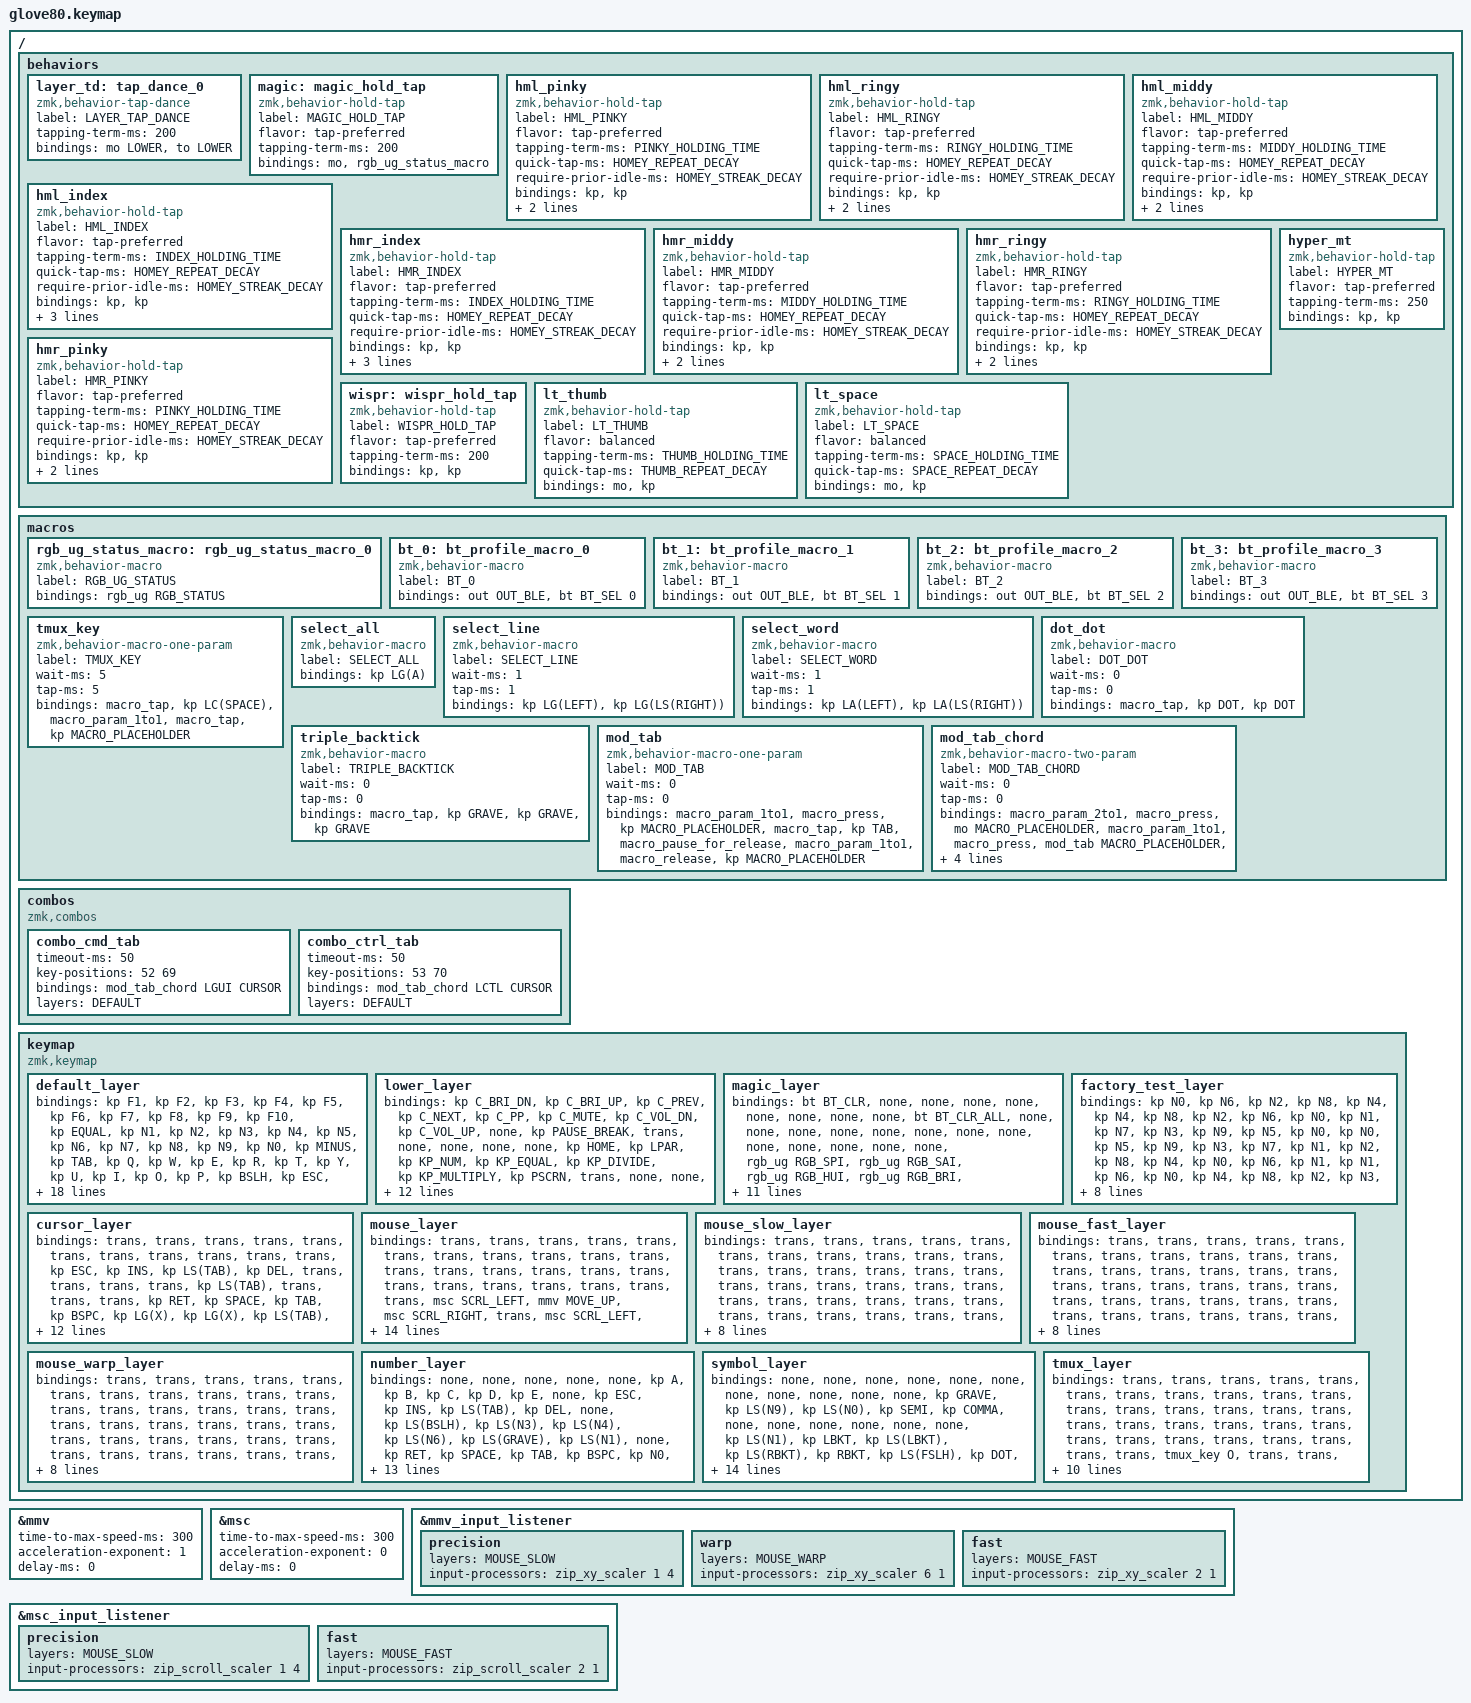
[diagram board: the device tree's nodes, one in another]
// V2 — Home Row Mods (HRM), sunaku-flavored, layered onto V1 stock baseline.
// V1 (verbatim moergo-sc/glove80-zmk-config@34888be8) is preserved in git history
// at commit a61129d. This file diverges from V1 only on the default_layer's home
// row (row 4), where A/S/D/F and J/K/L/; become home row mods.
//
// HRM terminology (defined here on first use):
//   - HRM (Home Row Mod): a key on the home row (A S D F or J K L ;) that
//     behaves as a letter when tapped and as a modifier (Shift/Ctrl/Alt/Cmd)
//     when held. The goal is to never reach away from the home row to chord.
//   - hold-tap behavior: a ZMK primitive — one key, two outputs, chosen by
//     whether you tapped or held it. Same primitive that powers V1's &layer_td.
//   - mod-tap (&mt): ZMK's stock hold-tap where the hold side is a modifier.
//     We don't use &mt directly because we need finer control than its defaults.
//   - positional hold-tap: a hold-tap that also checks WHICH other key was
//     pressed during the hold window. If the other key is on the same hand,
//     the HRM resolves to a tap (letter) instead of a hold (modifier). This is
//     the primary defense against accidental modifier activation during typing.
//   - bilateral combinations: the convention that modifier-key chords use one
//     hand to hold the modifier and the OTHER hand to tap the modified key.
//     The positional hold-tap (above) nudges you toward this: a same-hand
//     key pressed mid-hold makes the HRM resolve to a tap, not a modifier.
//   - hold-while-undecided: a ZMK property that pre-presses the hold side
//     during the "undecided" window so that releasing the key without pressing
//     anything else still types the tap letter. Powers SHIFT_FORGIVENESS.
//   - require-prior-idle-ms ("streak decay"): blocks the hold side from firing
//     if any key was pressed within the last N ms. The big anti-misfire knob.
//   - quick-tap-ms ("repeat decay"): if you tapped the key very recently, the
//     next press is forced to be a tap (lets you "tap-then-hold" for auto-repeat).
//   - conditional layer: a ZMK construct that auto-activates a layer when one
//     or more other layers are already active. (Not used in V2; mentioned for
//     vocabulary completeness because V3+ may use it.)
//
// HRM configuration knobs are grouped in the V2 CONFIGURATION block below.
// Change DIFFICULTY_LEVEL to retune all hold timings with one number.

/*
 * Copyright (c) 2020 The ZMK Contributors
 *
 * SPDX-License-Identifier: MIT
 */

#include <behaviors.dtsi>
#include <dt-bindings/zmk/keys.h>
#include <dt-bindings/zmk/bt.h>
#include <dt-bindings/zmk/ext_power.h>
#include <dt-bindings/zmk/outputs.h>
#include <dt-bindings/zmk/rgb.h>
#include <dt-bindings/zmk/pointing.h>
#include <input/processors.dtsi>

#define HYPER LC(LS(LG(LALT)))

// =============================================================================
// V2 CONFIGURATION (sunaku-flavored HRM)
// =============================================================================

// OPERATING_SYSTEM — affects modifier order. Long-term goal of this repo is a
// macOS keyboard workflow, so we use macOS-tuned CAGS order. On macOS, Cmd is
// the everyday-shortcut modifier (Cmd+C, Cmd+V), so it lives on the strong
// middle finger where Linux/Windows put Ctrl. CAGS = Ctrl / Alt / Cmd / Shift.
#define OPERATING_SYSTEM 'M'

// DIFFICULTY_LEVEL — sunaku's noob-friendly sensitivity preset.
//   1 = 500 ms (very slow, very safe)
//   2 = 400 ms (slower, safe)
//   3 = 300 ms (normal)
//   4 = 200 ms (faster)               <-- current
//   5 = 100 ms (expert, lots of misfires until your hands learn)
// Bump it up as your fingers get used to HRM. Lower the number, longer the
// hold needed before a key counts as a modifier.
#define DIFFICULTY_LEVEL 4

// TAPPING_RESOLUTION — the "base" hold time derived from DIFFICULTY_LEVEL.
// Formula matches sunaku exactly: level 4 → (6 - 4) * 100 = 200 ms.
// Per-finger holding times are offsets ON TOP of this number, see below.
#define TAPPING_RESOLUTION ((6 - DIFFICULTY_LEVEL) * 100)

// Per-finger holding times. Weaker fingers (pinky) get more time so a
// natural slower press doesn't accidentally fire the modifier. Sunaku's
// offsets: index +30, middle +60, ring +90, pinky +120. With level 4:
//   index  =  230 ms (shift — fastest, because shift is most natural to hold)
//   middle =  260 ms (cmd on macOS)
//   ring   =  290 ms (alt)
//   pinky  =  320 ms (ctrl — slowest, because pinky is the weakest finger)
#define INDEX_HOLDING_TIME (TAPPING_RESOLUTION + 30)
#define MIDDY_HOLDING_TIME (TAPPING_RESOLUTION + 60)
#define RINGY_HOLDING_TIME (TAPPING_RESOLUTION + 90)
#define PINKY_HOLDING_TIME (TAPPING_RESOLUTION + 120)

// HOMEY_STREAK_DECAY — the "require-prior-idle-ms" value. If you typed any key
// in the last N ms, the HRM is FORCED to resolve as a tap. This is the big
// anti-misfire knob for typing. Level 4 → 200 ms of idle required before an
// HRM can resolve as a modifier. Sounds long, but it only kicks in mid-word.
#define HOMEY_STREAK_DECAY TAPPING_RESOLUTION

// HOMEY_REPEAT_DECAY — the "quick-tap-ms" value. If you tapped the same HRM
// in the last N ms, the next press resolves as a tap (letter). Lets you do
// "tap, then hold" for OS-level key auto-repeat: tap A once, hold A → "aaaa".
#define HOMEY_REPEAT_DECAY (TAPPING_RESOLUTION + 150)

// THUMB_HOLDING_TIME / THUMB_REPEAT_DECAY — timing for the thumb layer-tap keys
// (Backspace→Cursor, Enter→Mouse). Matches sunaku: thumbs get a little MORE
// hold time than the home row (+50 on the base) because a thumb resting on its
// key shouldn't trip the layer. quick-tap lets a fast double-press auto-repeat
// the tapped key. Both scale with DIFFICULTY_LEVEL like the home row timings.
#define THUMB_HOLDING_TIME (TAPPING_RESOLUTION + 50)
#define THUMB_REPEAT_DECAY (TAPPING_RESOLUTION + 150)

// SPACE_* — the Symbol layer lives on the Space thumb (tap Space, hold Symbol).
// Space is the most-pressed key, so it gets its own behavior: same balanced
// flavor and hold time as the thumbs, but a SHORTER quick-tap window
// (TAPPING_RESOLUTION) so tap-then-type isn't swallowed as auto-repeat. Matches
// sunaku's defaults. (He also offers an opt-in "space forgiveness" mode —
// tap-preferred + retro-tap — for fewer misfires; left off here to match him.)
#define SPACE_HOLDING_TIME THUMB_HOLDING_TIME
#define SPACE_REPEAT_DECAY TAPPING_RESOLUTION

// =============================================================================
// V3 MOUSE CONFIGURATION
// =============================================================================
// Tuning the ZMK pointing subsystem. Defaults are conservative; these values
// match sunaku's choices and feel reactive without being twitchy on 1440p+.
//
// MOUSE_MOVE_MAX — peak cursor speed (pixels per tick at full speed).
//   Higher = cursor crosses screen faster. 600 is sunaku's default for HiDPI.
// MOUSE_SCROLL_MAX — peak scroll speed (lines per tick).
//   Lower than move because scroll is per-line, not per-pixel.
// MOUSE_TIME_TO_MAX — ramp duration from 0 to peak (ms).
//   300 ms feels real-mouse-like; <200 ms is twitchy; >500 ms feels sluggish.
// MOUSE_ACCEL_EXP — 0 = linear ramp, 1 = quadratic (gaming-mouse feel).
#define ZMK_POINTING_DEFAULT_MOVE_VAL 600
#define ZMK_POINTING_DEFAULT_SCRL_VAL 20

// CAGS modifier order (macOS-tuned). Pinky → index = Ctrl, Alt, Cmd, Shift.
// Mirrored on both hands. On macOS, Cmd lands on the strong middle finger
// where Ctrl lives on Linux/Windows — because Cmd is the everyday shortcut
// modifier in macOS (Cmd+C, Cmd+V, Cmd+Tab).
#define LH_PINKY_MOD LCTL
#define LH_RINGY_MOD LALT
#define LH_MIDDY_MOD LGUI
#define LH_INDEX_MOD LSFT
#define RH_INDEX_MOD LSFT
#define RH_MIDDY_MOD LGUI
#define RH_RINGY_MOD LALT
#define RH_PINKY_MOD LCTL

// SHIFT_FORGIVENESS — on. When you hold a shift HRM and release it without
// pressing another key, the underlying letter (F or J) is typed instead of
// nothing. Prevents the "I lingered too long and nothing happened" surprise.
// Implemented via the `hold-while-undecided` ZMK property on the two index
// HRMs. Available in our pinned ZMK (v25.11, well past the v24.08-beta1
// threshold required for `hold-while-undecided`).

// BILATERAL COMBINATIONS — enforced by the positional hold-tap, not by a
// dedicated layer. Each HRM's hold-trigger-key-positions lists the OPPOSITE
// hand, so a same-hand key pressed during the hold window makes the HRM resolve
// to a tap (letter) instead of a modifier. That is what stops same-hand
// misfires while typing. A deliberately held modifier still applies to whatever
// you press next, same hand included — that is inherent to home row mods
// (sunaku's behave the same way), not something the firmware can prevent.

// Glove80 key-position numbering (sunaku's layout — used by hold-trigger-key-positions).
// 80 keys total, numbered 0–79. Left hand = positions 0–51, 64–71, plus split
// thumbs 52–54, 69–71. Right hand = positions 5–9 + 16–21 + 28–33 + 40–45 +
// 58–63 + 75–79 + thumbs 55–57, 72–74. Used by ZMK to decide if "the other
// key I just pressed" is on the same hand or the opposite hand.
//
// Visual:
//   |------------------------|------------------------|
//   | LEFT_HAND_KEYS         |        RIGHT_HAND_KEYS |
//   |                        |                        |
//   |  0  1  2  3  4         |          5  6  7  8  9 |
//   | 10 11 12 13 14 15      |      16 17 18 19 20 21 |
//   | 22 23 24 25 26 27      |      28 29 30 31 32 33 |
//   | 34 35 36 37 38 39      |      40 41 42 43 44 45 |
//   | 46 47 48 49 50 51      |      58 59 60 61 62 63 |
//   | 64 65 66 67 68         |         75 76 77 78 79 |
//   |                69 52   |   57 74                |
//   |                 70 53  |  56 73                 |
//   |                  71 54 | 55 72                  |
//   |------------------------|------------------------|

#define LEFT_HAND_KEYS  \
     0  1  2  3  4      \
    10 11 12 13 14 15   \
    22 23 24 25 26 27   \
    34 35 36 37 38 39   \
    46 47 48 49 50 51   \
    64 65 66 67 68      \
    52 53 54 69 70 71

#define RIGHT_HAND_KEYS \
     5  6  7  8  9      \
    16 17 18 19 20 21   \
    28 29 30 31 32 33   \
    40 41 42 43 44 45   \
    58 59 60 61 62 63   \
    75 76 77 78 79      \
    55 56 57 72 73 74

// =============================================================================
// LAYER NUMBERS
// =============================================================================
// V1 layers preserved. V3 adds CURSOR + MOUSE + three Mouse speed sublayers.
// V4 adds NUMBER + SYMBOL (Miryoku-style bilateral layers).
#define DEFAULT      0
#define LOWER        1
#define MAGIC        2
#define FACTORY_TEST 3
#define CURSOR       4
#define MOUSE        5
#define MOUSE_SLOW   6
#define MOUSE_FAST   7
#define MOUSE_WARP   8
#define NUMBER       9
#define SYMBOL       10
#define TMUX         11

/ {
    behaviors {
        // V1 tap-dance for the LOWER thumb key (unchanged).
        // First tap (or hold) = momentary, second tap = toggle.
        layer_td: tap_dance_0 {
            compatible = "zmk,behavior-tap-dance";
            label = "LAYER_TAP_DANCE";
            #binding-cells = <0>;
            tapping-term-ms = <200>;
            bindings = <&mo LOWER>, <&to LOWER>;
        };

        // V1 magic-key hold-tap (unchanged).
        // Hold = MAGIC layer, tap = RGB status indicator macro.
        magic: magic_hold_tap {
            compatible = "zmk,behavior-hold-tap";
            label = "MAGIC_HOLD_TAP";
            #binding-cells = <2>;
            flavor = "tap-preferred";
            tapping-term-ms = <200>;
            bindings = <&mo>, <&rgb_ug_status_macro>;
        };

        // =====================================================================
        // V2 home row mod hold-tap behaviors (8 total: 4 per hand, one per finger)
        // =====================================================================
        // Naming: hml_* = HRM Left, hmr_* = HRM Right. Suffix is the finger.
        //
        // Each behavior is a positional hold-tap:
        //   - flavor = tap-preferred: only resolves to hold if you actually
        //     hold past the tapping-term. Safest for fast typists.
        //   - tapping-term-ms: how long to hold before "hold" can fire.
        //   - quick-tap-ms (HOMEY_REPEAT_DECAY): tap-then-hold = auto-repeat.
        //   - require-prior-idle-ms (HOMEY_STREAK_DECAY): blocks holds during
        //     fast typing streaks.
        //   - hold-trigger-key-positions: only resolve as hold if the second
        //     key is on the OPPOSITE hand. Same-hand presses force a tap.
        //   - hold-trigger-on-release: defers the position check until release,
        //     letting fast rolls on the same hand resolve cleanly as taps.
        //   - bindings = <&kp>, <&kp>: hold side presses the modifier, the
        //     tap side types the letter (standard mod-tap).
        //   - hold-while-undecided: on the index/shift HRMs only, enables
        //     SHIFT_FORGIVENESS (release without other keypress → type the
        //     letter instead of nothing).

        // ---- LEFT HAND ----

        hml_pinky: hml_pinky {
            compatible = "zmk,behavior-hold-tap";
            label = "HML_PINKY";
            #binding-cells = <2>;
            flavor = "tap-preferred";
            tapping-term-ms = <PINKY_HOLDING_TIME>;
            quick-tap-ms = <HOMEY_REPEAT_DECAY>;
            require-prior-idle-ms = <HOMEY_STREAK_DECAY>;
            bindings = <&kp>, <&kp>;
            hold-trigger-key-positions = <RIGHT_HAND_KEYS>;
            hold-trigger-on-release;
        };

        hml_ringy: hml_ringy {
            compatible = "zmk,behavior-hold-tap";
            label = "HML_RINGY";
            #binding-cells = <2>;
            flavor = "tap-preferred";
            tapping-term-ms = <RINGY_HOLDING_TIME>;
            quick-tap-ms = <HOMEY_REPEAT_DECAY>;
            require-prior-idle-ms = <HOMEY_STREAK_DECAY>;
            bindings = <&kp>, <&kp>;
            hold-trigger-key-positions = <RIGHT_HAND_KEYS>;
            hold-trigger-on-release;
        };

        hml_middy: hml_middy {
            compatible = "zmk,behavior-hold-tap";
            label = "HML_MIDDY";
            #binding-cells = <2>;
            flavor = "tap-preferred";
            tapping-term-ms = <MIDDY_HOLDING_TIME>;
            quick-tap-ms = <HOMEY_REPEAT_DECAY>;
            require-prior-idle-ms = <HOMEY_STREAK_DECAY>;
            bindings = <&kp>, <&kp>;
            hold-trigger-key-positions = <RIGHT_HAND_KEYS>;
            hold-trigger-on-release;
        };

        // Index finger HRMs get hold-while-undecided for SHIFT_FORGIVENESS.
        hml_index: hml_index {
            compatible = "zmk,behavior-hold-tap";
            label = "HML_INDEX";
            #binding-cells = <2>;
            flavor = "tap-preferred";
            tapping-term-ms = <INDEX_HOLDING_TIME>;
            quick-tap-ms = <HOMEY_REPEAT_DECAY>;
            require-prior-idle-ms = <HOMEY_STREAK_DECAY>;
            bindings = <&kp>, <&kp>;
            hold-trigger-key-positions = <RIGHT_HAND_KEYS>;
            hold-trigger-on-release;
            hold-while-undecided;
        };

        // ---- RIGHT HAND ----

        // Index finger HRM, mirrored. SHIFT_FORGIVENESS on this one too.
        hmr_index: hmr_index {
            compatible = "zmk,behavior-hold-tap";
            label = "HMR_INDEX";
            #binding-cells = <2>;
            flavor = "tap-preferred";
            tapping-term-ms = <INDEX_HOLDING_TIME>;
            quick-tap-ms = <HOMEY_REPEAT_DECAY>;
            require-prior-idle-ms = <HOMEY_STREAK_DECAY>;
            bindings = <&kp>, <&kp>;
            hold-trigger-key-positions = <LEFT_HAND_KEYS>;
            hold-trigger-on-release;
            hold-while-undecided;
        };

        hmr_middy: hmr_middy {
            compatible = "zmk,behavior-hold-tap";
            label = "HMR_MIDDY";
            #binding-cells = <2>;
            flavor = "tap-preferred";
            tapping-term-ms = <MIDDY_HOLDING_TIME>;
            quick-tap-ms = <HOMEY_REPEAT_DECAY>;
            require-prior-idle-ms = <HOMEY_STREAK_DECAY>;
            bindings = <&kp>, <&kp>;
            hold-trigger-key-positions = <LEFT_HAND_KEYS>;
            hold-trigger-on-release;
        };

        hmr_ringy: hmr_ringy {
            compatible = "zmk,behavior-hold-tap";
            label = "HMR_RINGY";
            #binding-cells = <2>;
            flavor = "tap-preferred";
            tapping-term-ms = <RINGY_HOLDING_TIME>;
            quick-tap-ms = <HOMEY_REPEAT_DECAY>;
            require-prior-idle-ms = <HOMEY_STREAK_DECAY>;
            bindings = <&kp>, <&kp>;
            hold-trigger-key-positions = <LEFT_HAND_KEYS>;
            hold-trigger-on-release;
        };

        hmr_pinky: hmr_pinky {
            compatible = "zmk,behavior-hold-tap";
            label = "HMR_PINKY";
            #binding-cells = <2>;
            flavor = "tap-preferred";
            tapping-term-ms = <PINKY_HOLDING_TIME>;
            quick-tap-ms = <HOMEY_REPEAT_DECAY>;
            require-prior-idle-ms = <HOMEY_STREAK_DECAY>;
            bindings = <&kp>, <&kp>;
            hold-trigger-key-positions = <LEFT_HAND_KEYS>;
            hold-trigger-on-release;
        };

        // V3: wispr hold-tap for Wispr Flow dictation.
        //   HOLD = F18 (push-to-talk), TAP = F19 (toggle)
        //
        // tap-preferred: only resolves to hold if held past tapping-term-ms.
        // Safer for a frequently-tapped key — better to miss a push-to-talk
        // than misfire it.
        wispr: wispr_hold_tap {
            compatible = "zmk,behavior-hold-tap";
            label = "WISPR_HOLD_TAP";
            #binding-cells = <2>;
            flavor = "tap-preferred";
            tapping-term-ms = <200>;
            bindings = <&kp>, <&kp>;
        };

        // V3: Hyper hold-tap.
        // Used on the LH upper-outer thumb (replaces redundant LSHFT).
        // tap-preferred: a brief hold + release types LSHFT, not Hyper.
        // Higher tapping-term than wispr because Hyper triggers OS-level
        // keyboard automations (Raycast, Hammerspoon) where misfires are
        // user-visible — better to require a deliberate hold.
        hyper_mt: hyper_mt {
            compatible = "zmk,behavior-hold-tap";
            label = "HYPER_MT";
            #binding-cells = <2>;
            flavor = "tap-preferred";
            tapping-term-ms = <250>;
            bindings = <&kp>, <&kp>;
        };

        // V4: thumb layer-tap. Tap = the keycode, hold = the layer.
        //   &lt_thumb CURSOR BSPC  → tap Backspace, hold Cursor (LH thumb)
        //   &lt_thumb MOUSE  RET   → tap Enter,     hold Mouse  (RH thumb)
        //
        // flavor = "balanced": the layer engages as soon as you press another
        // key while holding, but a quick press-and-release still emits the tap
        // key. This is sunaku's thumb flavor — snappier for layer access than
        // tap-preferred, which would force you to wait out the full hold first.
        lt_thumb: lt_thumb {
            compatible = "zmk,behavior-hold-tap";
            label = "LT_THUMB";
            #binding-cells = <2>;
            flavor = "balanced";
            tapping-term-ms = <THUMB_HOLDING_TIME>;
            quick-tap-ms = <THUMB_REPEAT_DECAY>;
            bindings = <&mo>, <&kp>;
        };

        // V4: dedicated spacebar layer-tap for the Symbol layer. Same balanced
        // flavor as lt_thumb, but its own quick-tap (SPACE_REPEAT_DECAY) so the
        // most-pressed key stays snappy. Tap = Space, hold = Symbol.
        lt_space: lt_space {
            compatible = "zmk,behavior-hold-tap";
            label = "LT_SPACE";
            #binding-cells = <2>;
            flavor = "balanced";
            tapping-term-ms = <SPACE_HOLDING_TIME>;
            quick-tap-ms = <SPACE_REPEAT_DECAY>;
            bindings = <&mo>, <&kp>;
        };
    };

    macros {
        // V1 macros (unchanged).
        rgb_ug_status_macro: rgb_ug_status_macro_0 {
            label = "RGB_UG_STATUS";
            compatible = "zmk,behavior-macro";
            #binding-cells = <0>;
            bindings
                = <&rgb_ug RGB_STATUS>;
        };

        bt_0: bt_profile_macro_0 {
            label = "BT_0";
            compatible = "zmk,behavior-macro";
            #binding-cells = <0>;
            bindings
                = <&out OUT_BLE>,
                  <&bt BT_SEL 0>;
        };

        bt_1: bt_profile_macro_1 {
            label = "BT_1";
            compatible = "zmk,behavior-macro";
            #binding-cells = <0>;
            bindings
                = <&out OUT_BLE>,
                  <&bt BT_SEL 1>;
        };

        bt_2: bt_profile_macro_2 {
            label = "BT_2";
            compatible = "zmk,behavior-macro";
            #binding-cells = <0>;
            bindings
                = <&out OUT_BLE>,
                  <&bt BT_SEL 2>;
        };

        bt_3: bt_profile_macro_3 {
            label = "BT_3";
            compatible = "zmk,behavior-macro";
            #binding-cells = <0>;
            bindings
                = <&out OUT_BLE>,
                  <&bt BT_SEL 3>;
        };

        // tmux helper: send the prefix (Ctrl+Space) then the passed key, so the
        // tmux layer can map one keypress to a full "prefix then X" command.
        tmux_key: tmux_key {
            label = "TMUX_KEY";
            compatible = "zmk,behavior-macro-one-param";
            #binding-cells = <1>;
            wait-ms = <5>;
            tap-ms = <5>;
            bindings
                = <&macro_tap &kp LC(SPACE)>
                , <&macro_param_1to1>
                , <&macro_tap &kp MACRO_PLACEHOLDER>;
        };

        // =====================================================================
        // V3: selection-helper macros for the Cursor layer.
        // =====================================================================

        // select_all — Cmd+A. Wrapped as a macro (not a plain &kp) so the
        // Cursor layer can reference it by name like sunaku does.
        select_all: select_all {
            label = "SELECT_ALL";
            compatible = "zmk,behavior-macro";
            #binding-cells = <0>;
            bindings = <&kp LG(A)>;
        };

        // select_line — jump to start of line, then shift+select to end.
        // macOS line-start is Cmd+Left; line-end is Cmd+Right.
        select_line: select_line {
            label = "SELECT_LINE";
            compatible = "zmk,behavior-macro";
            #binding-cells = <0>;
            wait-ms = <1>;
            tap-ms = <1>;
            bindings = <&kp LG(LEFT)>, <&kp LG(LS(RIGHT))>;
        };

        // select_word — jump to start of word, then shift+select to end.
        // macOS word-start is Option+Left; word-end is Option+Right.
        select_word: select_word {
            label = "SELECT_WORD";
            compatible = "zmk,behavior-macro";
            #binding-cells = <0>;
            wait-ms = <1>;
            tap-ms = <1>;
            bindings = <&kp LA(LEFT)>, <&kp LA(LS(RIGHT))>;
        };

        // V4: text macros used by the Symbol layer (ported from sunaku).
        // dot_dot types ".." (for ../ paths); triple_backtick types "```"
        // (markdown code fences).
        dot_dot: dot_dot {
            label = "DOT_DOT";
            compatible = "zmk,behavior-macro";
            #binding-cells = <0>;
            wait-ms = <0>;
            tap-ms = <0>;
            bindings = <&macro_tap &kp DOT &kp DOT>;
        };

        triple_backtick: triple_backtick {
            label = "TRIPLE_BACKTICK";
            compatible = "zmk,behavior-macro";
            #binding-cells = <0>;
            wait-ms = <0>;
            tap-ms = <0>;
            bindings = <&macro_tap &kp GRAVE &kp GRAVE &kp GRAVE>;
        };

        // V5: app-switching swapper (ported from sunaku). mod_tab presses a
        // modifier, taps Tab once, then HOLDS the modifier until released —
        // macOS Cmd+Tab (and Ctrl+Tab) need the modifier held across taps.
        // mod_tab_chord wraps it so a thumb combo also turns on a layer: you
        // keep tapping Tab / Shift+Tab on that layer to cycle, then release the
        // combo to commit. Two-param: <modifier> <layer>.
        mod_tab: mod_tab {
            label = "MOD_TAB";
            compatible = "zmk,behavior-macro-one-param";
            #binding-cells = <1>;
            wait-ms = <0>;
            tap-ms = <0>;
            bindings
                = <&macro_param_1to1>
                , <&macro_press &kp MACRO_PLACEHOLDER>
                , <&macro_tap &kp TAB>
                , <&macro_pause_for_release>
                , <&macro_param_1to1>
                , <&macro_release &kp MACRO_PLACEHOLDER>
                ;
        };

        mod_tab_chord: mod_tab_chord {
            label = "MOD_TAB_CHORD";
            compatible = "zmk,behavior-macro-two-param";
            #binding-cells = <2>;
            wait-ms = <0>;
            tap-ms = <0>;
            bindings
                = <&macro_param_2to1>
                , <&macro_press &mo MACRO_PLACEHOLDER>
                , <&macro_param_1to1>
                , <&macro_press &mod_tab MACRO_PLACEHOLDER>
                , <&macro_pause_for_release>
                , <&macro_param_1to1>
                , <&macro_release &mod_tab MACRO_PLACEHOLDER>
                , <&macro_param_2to1>
                , <&macro_release &mo MACRO_PLACEHOLDER>
                ;
        };
    };

    // V5: thumb-pinch combos for app/tab switching. Press the two adjacent
    // left-thumb keys of a row together → starts a switcher: modifier held +
    // Cursor layer on + first Tab. Keep the pinch held and tap Tab / Shift+Tab
    // (already on the Cursor layer) to cycle either direction; release to commit.
    // Scoped to DEFAULT so they never fire while you're inside another layer.
    //   top row    (Hyper 52 + Backspace 69) → Cmd+Tab  (LGUI)
    //   middle row (Ctrl  53 + Delete    70) → Ctrl+Tab (LCTL)
    // 50 ms window → a deliberate simultaneous pinch, not a normal one-key tap.
    combos {
        compatible = "zmk,combos";

        combo_cmd_tab {
            timeout-ms = <50>;
            key-positions = <52 69>;
            bindings = <&mod_tab_chord LGUI CURSOR>;
            layers = <DEFAULT>;
        };

        combo_ctrl_tab {
            timeout-ms = <50>;
            key-positions = <53 70>;
            bindings = <&mod_tab_chord LCTL CURSOR>;
            layers = <DEFAULT>;
        };
    };

    keymap {
        compatible = "zmk,keymap";

        // default_layer: QWERTY base. V2 modifies ONLY row 4 (the home row).
        // A/S/D/F and J/K/L/; now use hold-tap behaviors. Everything else is
        // identical to V1.
        default_layer {
            // ---------------------------------------------------------------------------------------------------------------------------------
            // |  F1   |  F2 |  F3 |  F4  |  F5  |                                                               |  F6   |  F7   |  F8  |   F9  |  F10 |
            // |  =    |  1  |  2  |  3   |  4   |  5   |                                                 |  6   |   7   |   8   |  9   |   0   |   -  |
            // |  TAB  |  Q  |  W  |  E   |  R   |  T   |                                                 |  Y   |   U   |   I   |  O   |   P   |   \  |
            // |  ESC  | A*  | S*  |  D*  |  F*  |  G   |                                                 |  H   |  J*   |  K*   | L*   |  ;*   |   '  |
            // |   `   |  Z  |  X  |  C   |  V   |  B   | LSHFT | LCTRL | LOWER | | LGUI  | RCTRL | RSHFT |  N   |   M   |   ,   |  .   |   /   | PGUP |
            // | MAGIC | HOME| END | LEFT | RIGHT|      | BSPC† | DEL†  | LALT  | | RALT  | RET†  | SPACE†|      |  UP   | DOWN  |  [   |   ]   | PGDN |
            //
            // Starred keys (A* S* D* F* J* K* L* ;*) on row 4 are HRM hold-taps:
            //   Tap → letter. Hold → modifier (CAGS on macOS: Ctrl/Alt/Cmd/Shift).
            // Daggered thumb keys (BSPC† DEL† RET† SPACE†) are layer-taps:
            //   BSPC† → tap Bksp, hold Cursor.    DEL†  → tap Del, hold Number.
            //   RET†  → tap Enter, hold Mouse.    SPACE† → tap Space, hold Symbol.

            bindings = <
            &kp F1         &kp F2   &kp F3      &kp F4      &kp F5                                                                                                                  &kp F6  &kp F7                &kp F8                &kp F9                &kp F10
            &kp EQUAL      &kp N1   &kp N2      &kp N3      &kp N4      &kp N5                                                                                              &kp N6  &kp N7  &kp N8                &kp N9                &kp N0                &kp MINUS
            &kp TAB        &kp Q    &kp W       &kp E       &kp R       &kp T                                                                                               &kp Y   &kp U   &kp I                 &kp O                 &kp P                 &kp BSLH
            &kp ESC        &hml_pinky LH_PINKY_MOD A   &hml_ringy LH_RINGY_MOD S   &hml_middy LH_MIDDY_MOD D   &hml_index LH_INDEX_MOD F   &kp G                                     &kp H   &hmr_index RH_INDEX_MOD J   &hmr_middy RH_MIDDY_MOD K   &hmr_ringy RH_RINGY_MOD L   &hmr_pinky RH_PINKY_MOD SEMI   &kp SQT
            &kp GRAVE      &kp Z    &kp X       &kp C       &kp V       &kp B   &hyper_mt HYPER LSHFT &kp LCTRL   &layer_td  &kp LG(SPACE)  &kp RCTRL &wispr LG(F18) LG(F19)                        &kp N   &kp M   &kp COMMA             &kp DOT               &kp FSLH              &kp PG_UP
            &magic MAGIC 0 &kp HOME &kp END     &kp LEFT    &kp RIGHT           &lt_thumb CURSOR BSPC  &lt_thumb NUMBER DEL  &kp LALT   &lt_thumb TMUX LC(SPACE)  &lt_thumb MOUSE RET  &lt_space SYMBOL SPACE                  &kp UP  &kp DOWN              &kp LBKT              &kp RBKT              &kp PG_DN
            >;
        };

        // lower_layer: V1 unchanged. Media controls, navigation, function keys, numpad.
        lower_layer {
            bindings = <
            &kp C_BRI_DN      &kp C_BRI_UP        &kp C_PREV      &kp C_NEXT      &kp C_PP                                                                                                           &kp C_MUTE   &kp C_VOL_DN &kp C_VOL_UP  &none           &kp PAUSE_BREAK
            &trans            &none               &none           &none           &none           &kp HOME                                                                              &kp LPAR     &kp KP_NUM   &kp KP_EQUAL &kp KP_DIVIDE &kp KP_MULTIPLY &kp PSCRN
            &trans            &none               &none           &kp UP          &none           &kp END                                                                               &kp RPAR     &kp KP_N7    &kp KP_N8    &kp KP_N9     &kp KP_MINUS    &kp SLCK
            &trans            &none               &kp LEFT        &kp DOWN        &kp RIGHT       &kp PG_UP                                                                             &kp PRCNT    &kp KP_N4    &kp KP_N5    &kp KP_N6     &kp KP_PLUS     &none
            &trans            &kp K_CMENU         &none           &kp F11         &kp F12         &kp PG_DN       &trans      &trans      &to DEFAULT &trans      &trans      &trans    &kp COMMA    &kp KP_N1    &kp KP_N2    &kp KP_N3     &kp KP_ENTER    &trans
            &trans            &kp CAPS            &kp INS         &kp F11         &kp F12                         &trans      &trans      &trans      &trans      &trans      &trans                 &kp KP_N0    &kp KP_N0    &kp KP_DOT    &kp KP_ENTER    &trans
            >;
        };

        // magic_layer: V1 unchanged. RGB, Bluetooth, system reset.
        magic_layer {
            bindings = <
            &bt BT_CLR        &none               &none           &none           &none                                                                                                           &none      &none      &none      &none      &bt BT_CLR_ALL
            &none             &none               &none           &none           &none           &none                                                                                &none      &none      &none      &none      &none      &none
            &none             &rgb_ug RGB_SPI     &rgb_ug RGB_SAI &rgb_ug RGB_HUI &rgb_ug RGB_BRI &rgb_ug RGB_TOG                                                                      &none      &none      &none      &none      &none      &none
            &bootloader       &rgb_ug RGB_SPD     &rgb_ug RGB_SAD &rgb_ug RGB_HUD &rgb_ug RGB_BRD &rgb_ug RGB_EFF                                                                      &none      &none      &none      &none      &none      &bootloader
            &sys_reset        &none               &none           &none           &none           &none           &bt_2     &bt_3     &none            &none     &none     &none       &none      &none      &none      &none      &none      &sys_reset
            &none             &none               &none           &none           &none                           &bt_0     &bt_1     &out OUT_USB     &none     &none     &none                  &none      &none      &none      &none      &to FACTORY_TEST
            >;
        };

        // factory_test_layer: V1 unchanged. Manufacturing QA.
        factory_test_layer {
            bindings = <
            &kp N0   &kp N6   &kp N2   &kp N8   &kp N4                                                                              &kp N4   &kp N8   &kp N2   &kp N6   &kp N0
            &kp N1   &kp N7   &kp N3   &kp N9   &kp N5   &kp N0                                                            &kp N0   &kp N5   &kp N9   &kp N3   &kp N7   &kp N1
            &kp N2   &kp N8   &kp N4   &kp N0   &kp N6   &kp N1                                                            &kp N1   &kp N6   &kp N0   &kp N4   &kp N8   &kp N2
            &kp N3   &kp N9   &kp N5   &kp N1   &kp N7   &kp N2                                                            &kp N2   &kp N7   &kp N1   &kp N5   &kp N9   &kp N3
            &kp N4   &kp N0   &kp N6   &kp N2   &kp N8   &kp N3   &kp N4   &kp N5   &kp N6      &kp N6   &kp N5   &kp N4   &kp N3   &kp N8   &kp N2   &kp N6   &kp N0   &kp N4
            &kp N5   &kp N1   &kp N7   &kp N3   &kp N9            &kp N7   &kp N8   &kp N9      &kp N9   &kp N8   &kp N7            &kp N9   &kp N3   &kp N7   &kp N1   &kp N5
            >;
        };

        // =====================================================================
        // V3: CURSOR layer (text navigation). Stubbed in Task 2; filled in
        // Tasks 6–7. While stubbed, all positions are &trans → no behavior
        // change vs. V2.
        // =====================================================================
        cursor_layer {
            bindings = <
            &trans  &trans  &trans  &trans  &trans                                                                                          &trans  &trans  &trans  &trans  &trans
            &trans  &kp ESC  &kp INS  &kp LS(TAB)  &kp DEL  &trans                                                                  &trans  &trans  &trans  &kp LS(TAB)  &trans  &trans
            &trans  &kp RET  &kp SPACE  &kp TAB  &kp BSPC  &kp LG(X)                                                               &kp LG(X)  &kp LS(TAB)  &kp LG(Z)  &kp LG(LS(Z))  &kp TAB  &trans
            &sk LSHFT  &kp LCTRL  &kp LALT  &kp LGUI  &kp LSHFT  &kp LG(C)                                                        &kp LG(C)  &kp LEFT  &kp UP  &kp DOWN  &kp RIGHT  &sk LSHFT
            &kp LG(L)  &select_all  &select_line  &select_word  &kp LG(F)  &kp LG(V)  &trans  &trans  &trans  &trans  &trans  &trans  &kp LG(V)  &kp LG(LEFT)  &kp PG_UP  &kp PG_DN  &kp LG(RIGHT)  &kp LG(L)
            &kp LG(K)  &kp LG(Z)  &kp LG(LS(Z))  &kp LG(LS(G))  &kp LG(G)          &trans  &trans  &trans  &trans  &trans  &trans          &kp LG(F)  &kp LG(LS(G))  &kp LG(G)  &kp LG(H)  &kp LG(K)
            >;
        };

        // V3: MOUSE base layer — adapted from sunaku's Glorious Engrammer.
        //
        // Movement (inverted-T) on both hands; scroll mirrored on outer columns.
        //   LH row 2 (W/E/R):  scroll-left, MOVE_UP, scroll-right
        //   LH row 3 (A→G):    scroll-up,  MOVE_LEFT, MOVE_DOWN, MOVE_RIGHT, scroll-up
        //   LH row 4 (Z→B):    scroll-dn,  SLOW, WARP, FAST, scroll-dn
        //   LH row 5 (X/C/V):  cut, copy, paste
        //   LH thumb row 4:    MCLK, K_APP (context menu), MB5
        //   LH thumb row 5:    LCLK, RCLK, MB4   ← drag = hold LCLK on T5
        //
        //   RH row 2 (Y→P):    scroll-left, LCLK, MCLK, RCLK, scroll-right
        //   RH row 3 (H→;):    scroll-up,  FAST, WARP, SLOW, K_APP, MB4
        //   RH row 4 (N→/):    scroll-dn,  MOVE_LEFT, MOVE_UP, MOVE_DOWN, MOVE_RIGHT, MB5
        //   RH thumb row 4:    cut, copy, paste
        //
        // Scroll keys appear at A/G/Y/P (vertical scroll up) and Z/B/N/PGUP
        // (down), so any single finger on either home row can reach scroll
        // without moving away from the movement cluster.
        mouse_layer {
            bindings = <
            &trans  &trans  &trans  &trans  &trans                                                                                                              &trans          &trans           &trans           &trans           &trans
            &trans  &trans  &trans  &trans  &trans  &trans                                                                                              &trans  &trans          &trans           &trans           &trans           &trans
            &trans  &trans  &msc SCRL_LEFT  &mmv MOVE_UP  &msc SCRL_RIGHT  &trans                                                              &msc SCRL_LEFT  &mkp LCLK       &mkp MCLK        &mkp RCLK        &msc SCRL_RIGHT  &trans
            &trans  &msc SCRL_UP  &mmv MOVE_LEFT  &mmv MOVE_DOWN  &mmv MOVE_RIGHT  &msc SCRL_UP                                                    &msc SCRL_UP  &mo MOUSE_FAST  &mo MOUSE_WARP   &mo MOUSE_SLOW   &kp K_APP        &mkp MB4
            &trans  &msc SCRL_DOWN  &mo MOUSE_SLOW  &mo MOUSE_WARP  &mo MOUSE_FAST  &msc SCRL_DOWN  &mkp MCLK  &kp K_APP  &mkp MB5  &kp LG(X)  &kp LG(C)  &kp LG(V)  &msc SCRL_DOWN  &mmv MOVE_LEFT  &mmv MOVE_UP     &mmv MOVE_DOWN   &mmv MOVE_RIGHT  &mkp MB5
            &trans  &trans  &kp LG(X)  &kp LG(C)  &kp LG(V)          &mkp LCLK  &mkp RCLK  &mkp MB4  &trans  &trans  &trans                          &trans          &trans           &trans           &trans           &trans
            >;
        };

        // V3: MOUSE_SLOW sublayer (precision). Same key positions as MOUSE,
        // but with reduced movement scaler (set up in Task 10). Filled Task 10.
        mouse_slow_layer {
            bindings = <
            &trans  &trans  &trans  &trans  &trans                                                                                          &trans  &trans  &trans  &trans  &trans
            &trans  &trans  &trans  &trans  &trans  &trans                                                                          &trans  &trans  &trans  &trans  &trans  &trans
            &trans  &trans  &trans  &trans  &trans  &trans                                                                          &trans  &trans  &trans  &trans  &trans  &trans
            &trans  &trans  &trans  &trans  &trans  &trans                                                                          &trans  &trans  &trans  &trans  &trans  &trans
            &trans  &trans  &trans  &trans  &trans  &trans  &trans  &trans  &trans  &trans  &trans  &trans                          &trans  &trans  &trans  &trans  &trans  &trans
            &trans  &trans  &trans  &trans  &trans          &trans  &trans  &trans  &trans  &trans  &trans                                  &trans  &trans  &trans  &trans  &trans
            >;
        };

        // V3: MOUSE_FAST sublayer (fast travel). Filled Task 10.
        mouse_fast_layer {
            bindings = <
            &trans  &trans  &trans  &trans  &trans                                                                                          &trans  &trans  &trans  &trans  &trans
            &trans  &trans  &trans  &trans  &trans  &trans                                                                          &trans  &trans  &trans  &trans  &trans  &trans
            &trans  &trans  &trans  &trans  &trans  &trans                                                                          &trans  &trans  &trans  &trans  &trans  &trans
            &trans  &trans  &trans  &trans  &trans  &trans                                                                          &trans  &trans  &trans  &trans  &trans  &trans
            &trans  &trans  &trans  &trans  &trans  &trans  &trans  &trans  &trans  &trans  &trans  &trans                          &trans  &trans  &trans  &trans  &trans  &trans
            &trans  &trans  &trans  &trans  &trans          &trans  &trans  &trans  &trans  &trans  &trans                                  &trans  &trans  &trans  &trans  &trans
            >;
        };

        // V3: MOUSE_WARP sublayer (screen-crossing). Filled Task 10.
        mouse_warp_layer {
            bindings = <
            &trans  &trans  &trans  &trans  &trans                                                                                          &trans  &trans  &trans  &trans  &trans
            &trans  &trans  &trans  &trans  &trans  &trans                                                                          &trans  &trans  &trans  &trans  &trans  &trans
            &trans  &trans  &trans  &trans  &trans  &trans                                                                          &trans  &trans  &trans  &trans  &trans  &trans
            &trans  &trans  &trans  &trans  &trans  &trans                                                                          &trans  &trans  &trans  &trans  &trans  &trans
            &trans  &trans  &trans  &trans  &trans  &trans  &trans  &trans  &trans  &trans  &trans  &trans                          &trans  &trans  &trans  &trans  &trans  &trans
            &trans  &trans  &trans  &trans  &trans          &trans  &trans  &trans  &trans  &trans  &trans                                  &trans  &trans  &trans  &trans  &trans
            >;
        };

        // V4: NUMBER layer (Miryoku-style, accessed by holding the LH Delete
        // thumb). RIGHT hand becomes a numpad — 7 8 9 / 4 5 6 / 1 2 3 / 0 — with
        // operators (- + * / = . , %) and brackets around it; hex letters A-E
        // ride the top row. LEFT hand keeps modifiers (Ctrl/Alt/Cmd/Shift, so
        // Cmd+digit works), select/find/undo/redo, and whitespace. The Delete
        // access key holds &tog so you can LOCK the layer for long number entry.
        number_layer {
            bindings = <
            &none       &none              &none              &none              &none                                                                                                  &kp A         &kp B       &kp C       &kp D       &kp E
            &none       &kp ESC            &kp INS            &kp LS(TAB)        &kp DEL            &none                                                                  &kp LS(BSLH)  &kp LS(N3)  &kp LS(N4)  &kp LS(N6)  &kp LS(GRAVE)  &kp LS(N1)
            &none       &kp RET            &kp SPACE          &kp TAB            &kp BSPC           &kp N0                                                                 &kp LS(G)     &kp N7      &kp N8      &kp N9      &kp LS(SEMI)   &kp LS(N5)
            &sk LSHFT   &kp LH_PINKY_MOD   &kp LH_RINGY_MOD   &kp LH_MIDDY_MOD   &kp LH_INDEX_MOD   &kp X                                                                  &kp K         &kp N4      &kp N5      &kp N6      &kp MINUS      &kp LS(EQUAL)
            &kp E       &select_all        &select_line       &select_word       &kp LG(F)          &kp F   &none  &none  &none      &kp LS(COMMA)  &kp EQUAL  &kp COMMA     &kp J         &kp N1      &kp N2      &kp N3      &kp FSLH       &kp LS(N8)
            &kp LS(MINUS)  &kp LG(Z)       &kp LG(LS(Z))      &kp LG(LS(G))      &kp LG(G)                  &none  &tog NUMBER  &none  &kp LS(DOT)  &kp DOT  &kp N0                  &kp LS(N9)    &kp LBKT    &kp RBKT    &kp LS(N0)  &kp LS(N2)
            >;
        };

        // V4: SYMBOL layer (Miryoku-style, accessed by holding the RH Space
        // thumb via the dedicated lt_space). LEFT hand becomes a symbol pad with
        // the common symbols on/around the home row (# ^ = _ $ * / ! [ { } ] ? /
        // ~ < | - > /). RIGHT hand keeps modifiers, whitespace, and a couple of
        // text macros (.. and ```). The Space access key holds &tog to lock it.
        symbol_layer {
            bindings = <
            &none         &none           &none           &none           &none                                                                                                       &none      &none      &none      &none      &none
            &none         &kp GRAVE       &kp LS(N9)      &kp LS(N0)      &kp SEMI        &kp COMMA                                                                          &none      &none      &none      &none      &none      &none
            &kp LS(N1)    &kp LBKT        &kp LS(LBKT)    &kp LS(RBKT)    &kp RBKT        &kp LS(FSLH)                                                                       &kp DOT    &kp DEL    &kp LS(TAB)  &kp INS  &kp ESC    &none
            &kp LS(N3)    &kp LS(N6)      &kp EQUAL       &kp LS(MINUS)   &kp LS(N4)      &kp LS(N8)                                                                         &kp COMMA  &kp BSPC   &kp TAB    &kp SPACE  &kp RET    &triple_backtick
            &kp LS(GRAVE) &kp LS(COMMA)   &kp LS(BSLH)    &kp MINUS       &kp LS(DOT)     &kp FSLH   &kp BSLH  &kp DOT  &kp LS(N8)  &none  &none  &none                      &kp SEMI   &kp LS(SQT)  &kp SQT  &kp GRAVE  &kp BSLH   &trans
            &dot_dot      &kp LS(N7)      &kp SQT         &kp LS(SQT)     &kp LS(EQUAL)              &kp LS(N5)  &kp LS(SEMI)  &kp LS(N2)  &none  &none  &tog SYMBOL          &kp RH_INDEX_MOD  &kp RH_MIDDY_MOD  &kp RH_RINGY_MOD  &kp RH_PINKY_MOD  &none
            >;
        };

        // tmux layer (hold the RH tmux thumb). Home row + neighbours become one-press
        // tmux commands via tmux_key (each sends prefix Ctrl+Space, then the key).
        //   right home  H/J/K/L = pane left/down/up/right
        //   left        S=session-tree  D=detach  Z=zoom  C=new-window  V=split|  B=split_
        //   right       N=next-window   M=prev-window
        //   right top   O = copy pane cwd to Mac clipboard (VS Code bridge; pairs with tmux.conf `bind o`)
        tmux_layer {
            bindings = <
            &trans  &trans  &trans  &trans  &trans                                                                                      &trans  &trans  &trans  &trans  &trans
            &trans  &trans  &trans  &trans  &trans  &trans                                                                      &trans  &trans  &trans  &trans  &trans  &trans
            &trans  &trans  &trans  &trans  &trans  &trans                                                                      &trans  &trans  &trans  &tmux_key O  &trans  &trans
            &trans  &trans  &tmux_key S  &tmux_key D  &trans  &trans                                                            &tmux_key H  &tmux_key J  &tmux_key K  &tmux_key L  &trans  &trans
            &trans  &tmux_key Z  &trans  &tmux_key C  &tmux_key LS(BSLH)  &tmux_key LS(MINUS)  &trans &trans &trans  &trans &trans &trans  &tmux_key N  &tmux_key P  &trans  &trans  &trans  &trans
            &trans  &trans  &trans  &trans  &trans  &trans &trans &trans  &trans &trans &trans  &trans  &trans  &trans  &trans  &trans
            >;
        };
    };
};

// =============================================================================
// V3: Mouse motion + scroll tuning.
// =============================================================================
// Reference overrides for the built-in &mmv (mouse move) and &msc (mouse
// scroll) behaviors. acceleration-exponent=1 = quadratic feel like a real
// mouse. time-to-max-speed-ms = ramp duration; 300 ms is sunaku's default.
// delay-ms=0: no artificial delay before movement starts.

&mmv {
    time-to-max-speed-ms = <300>;
    acceleration-exponent = <1>;
    delay-ms = <0>;
};

&msc {
    time-to-max-speed-ms = <300>;
    acceleration-exponent = <0>;
    delay-ms = <0>;
};

// =============================================================================
// V3: Input-listener speed scalers for Mouse sublayers.
// =============================================================================
// urob's input-listener pattern: instead of duplicating the MOUSE layer three
// times (one per speed), we use a single MOUSE layer and three zero-key sublayers
// (MOUSE_SLOW, MOUSE_FAST, MOUSE_WARP). When a sublayer is co-active, the
// listener intercepts every HID mouse-move event and applies the matching scaler
// before it reaches the host.
//
// zip_xy_scaler <numerator> <denominator> — multiplies raw motion by num/denom.
//   MOUSE_SLOW  = 1/4 (precision work: pixel-level drag, click on small targets)
//   MOUSE_FAST  = 2/1 (cross-pane sweeps without leaving the home row)
//   MOUSE_WARP  = 6/1 (full-screen jumps)
//
// zip_scroll_scaler does the same for scroll events. WARP is omitted from the
// scroll listener: a 6x scroll burst is almost never useful and easy to misfire.
//
// The three sublayer keymaps stay all-&trans — their only role is to signal
// the active scaler. No bindings needed.

&mmv_input_listener {
    precision {
        layers = <MOUSE_SLOW>;
        input-processors = <&zip_xy_scaler 1 4>;
    };
    warp {
        layers = <MOUSE_WARP>;
        input-processors = <&zip_xy_scaler 6 1>;
    };
    fast {
        layers = <MOUSE_FAST>;
        input-processors = <&zip_xy_scaler 2 1>;
    };
};

&msc_input_listener {
    precision {
        layers = <MOUSE_SLOW>;
        input-processors = <&zip_scroll_scaler 1 4>;
    };
    fast {
        layers = <MOUSE_FAST>;
        input-processors = <&zip_scroll_scaler 2 1>;
    };
};
